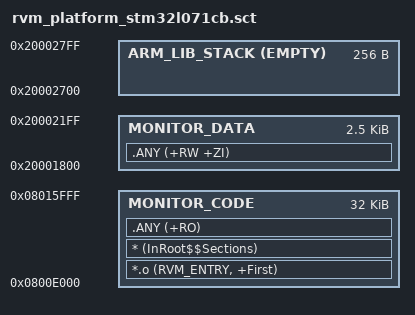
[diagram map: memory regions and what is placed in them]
;******************************************************************************
;Filename    : rvm_platform_stm32l071cb.sct
;Author      : The RVM project generator.
;Date        : 25/08/2024 17:37:30
;Licence     : Unlicense; see COPYING for details.
;Description : The scatter file for ARMv7-M layout. This file is intended
;              to be used with STM32L071CB.
;******************************************************************************

;Monitor **********************************************************************
MONITOR 0x800E000 0x8000
{
    ;Monitor code segment
    MONITOR_CODE 0x800E000 0x8000
    {
        ;The entry will be the first instruction
        *.o                    (RVM_ENTRY, +First)
        ;The lib code copying code
        *                      (InRoot$$Sections)
        ;The monitor code section
        .ANY                   (+RO)
    }

    ;Monitor data segment
    MONITOR_DATA 0x20001800 0xA00
    {
        .ANY                   (+RW +ZI)
    }

    ;Monitor stack segment - required by armlib; reusing the init thread's
    ARM_LIB_STACK 0x20002700 EMPTY 0x100
    {

    }
}
;End Monitor ******************************************************************

;End Of File ******************************************************************

;Copyright (C) Evo-Devo Instrum. All rights reserved **************************

